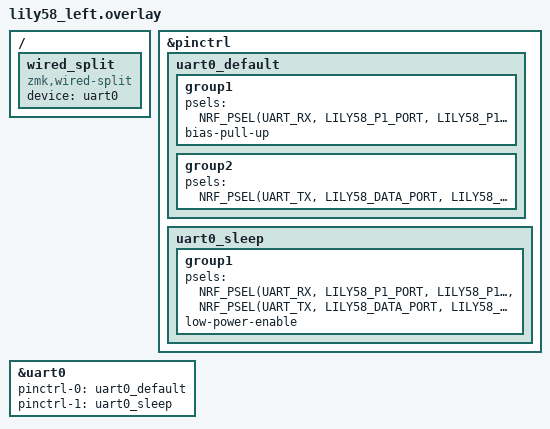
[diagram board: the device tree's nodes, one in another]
/*
 * Left (central): wired split over TRRS. Pins live in lily58-wired-pins.h.
 * Left TX -> DATA (J2 pad 3), left RX <- P1 (J2 pad 4).
 */
#include "lily58-wired-pins.h"

&pinctrl {
    uart0_default: uart0_default {
        group1 {
            psels = <NRF_PSEL(UART_RX, LILY58_P1_PORT, LILY58_P1_PIN)>;
            bias-pull-up;
        };
        group2 {
            psels = <NRF_PSEL(UART_TX, LILY58_DATA_PORT, LILY58_DATA_PIN)>;
        };
    };
    uart0_sleep: uart0_sleep {
        group1 {
            psels = <NRF_PSEL(UART_RX, LILY58_P1_PORT, LILY58_P1_PIN)>,
                    <NRF_PSEL(UART_TX, LILY58_DATA_PORT, LILY58_DATA_PIN)>;
            low-power-enable;
        };
    };
};

&uart0 {
    status = "okay";
    pinctrl-0 = <&uart0_default>;
    pinctrl-1 = <&uart0_sleep>;
    pinctrl-names = "default", "sleep";
};

/ {
    wired_split {
        compatible = "zmk,wired-split";
        device = <&uart0>;
    };
};
